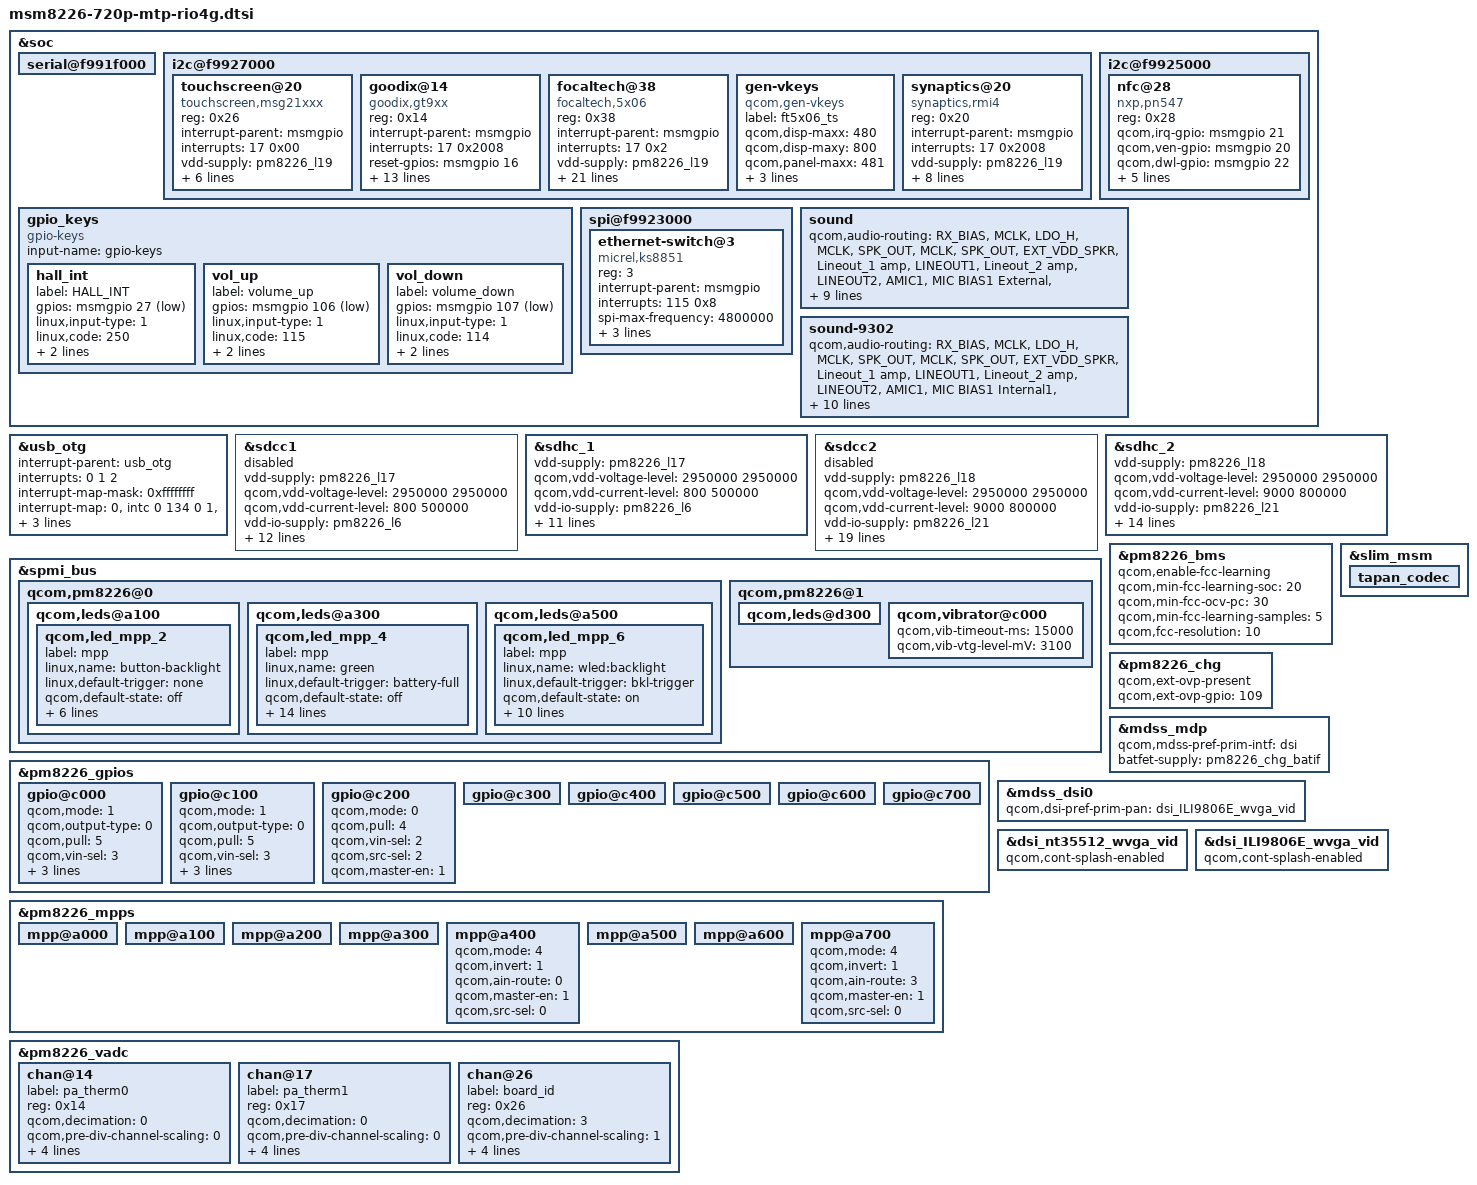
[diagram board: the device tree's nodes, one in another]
/* Copyright (c) 2013, The Linux Foundation. All rights reserved.
 *
 * This program is free software; you can redistribute it and/or modify
 * it under the terms of the GNU General Public License version 2 and
 * only version 2 as published by the Free Software Foundation.
 *
 * This program is distributed in the hope that it will be useful,
 * but WITHOUT ANY WARRANTY; without even the implied warranty of
 * MERCHANTABILITY or FITNESS FOR A PARTICULAR PURPOSE.  See the
 * GNU General Public License for more details.
 */

/* [PLATFORM]-Mod-BEGIN by TCTNB.WQF, 2013/08/15, rename the camera dtsi for rio4g */
/include/ "msm8226-camera-sensor-mtp-rio4g.dtsi"
/* [PLATFORM]-Mod-END by TCTNB.WQF */

&soc {
	serial@f991f000 {
		status = "ok";
	};

	i2c@f9927000 { /* BLSP1 QUP5 */
/*[PLATFORM]-ADD BGEIN by TCTNB.XQJ,07/31/2013,FR-487707,msg21 tp development,i2c address to 0x26.*/
                touchscreen@20 {
			compatible = "touchscreen,msg21xxx";
			reg = <0x26>;
			interrupt-parent = <&msmgpio>;
			interrupts = <17 0x00>;
			vdd-supply = <&pm8226_l19>;
			vcc_i2c-supply = <&pm8226_lvs1>;
			touchscreen,reset-gpio = <&msmgpio 16 0x00>;
			touchscreen,irq-gpio = <&msmgpio 17 0x00>;
			touchscreen,i2c-pull-up;
                        touchscreen,x_max=<480>;
                        touchscreen,y_max=<854>;
		};
/*[PLATFORM]-END by TCTNB.XQJ*/

/*[PLATFORM]-ADD BGEIN by TCTNB.XQJ,10/13/2013,FR-514195,GT915 tp MIATA development,i2c address to 0x14.,new cfg*/
	goodix@14 {
			compatible = "goodix,gt9xx";
			reg = <0x14>;
			interrupt-parent = <&msmgpio>;
			interrupts = <17 0x2008>;
			reset-gpios = <&msmgpio 16 0x00>;
			interrupt-gpios = <&msmgpio 17 0x00>;
                        vcc_i2c-supply = <&pm8226_lvs1>;
			avdd-supply =<&pm8226_l19>;/* <&tp_power>;*/
                        vdd-supply = <&pm8226_l19>;
			goodix,panel-coords =<0 0 540 1080>;
			goodix,display-coords = <0 0 540 960>;
			goodix,button-map= <158 102 139>;
                        regulator-min-microvolt = <2800000>;
                        regulator-max-microvolt = <2800000>;
			goodix,family-id = <0x0>;
                        goodix,i2c-pull-up;
			goodix,cfg-data = [ /*[BUGFIX]-MOD by TCTNB.XQJ,10/28/2013,FR-545213,double click wake,new cfg*/
                       45 1C 02 C0 03 05 34 01 01 0F 14 5F 3C 2D 03 05 00 00 00 00 88 
                       00 00 15 18 1D 14 8A 0A 0A 34 32 D3 07 00 00 00 83 02 1D 3C 01
                       00 00 00 00 00 00 00 00 00 28 64 94 C5 02 02 08 00 04 94 2C 00 
                       80 34 00 6C 3F 00 5D 4C 00 51 5B 00 51 10 30 48 00 F0 40 30 AA 
                       AA 27 00 00 00 00 00 00 00 00 00 00 00 00 00 00 00 00 00 00 00
                       00 00 00 00 00 00 00 02 04 06 08 0A 0C 0E 14 12 10 FF FF FF FF 
                       00 00 00 00 00 00 00 00 00 00 00 00 00 00 00 00 24 18 22 1C 21 
                       1D 20 1E 1F 16 02 0F 04 10 06 12 08 13 0A 00 FF FF FF FF FF FF
                       00 00 00 F5 FF FF FF FF FF FF FF FF 95 FF FF FF 7E 01
	         	];
		};
/*[PLATFORM]-END by TCTNB.XQJ*/
/*[PLATFORM]-MOD BGEIN by TCTNB.XQJ,12/06/2013,FR-553303,Add driver ft5x06.*/
       focaltech@38 {
			compatible ="focaltech,5x06";
			reg = <0x38>;
			interrupt-parent = <&msmgpio>;
			interrupts = <17 0x2>;
			vdd-supply = <&pm8226_l19>;
			vcc_i2c-supply = <&pm8226_lvs1>;
                        focaltech,name = "ft5x06";
			focaltech,family-id = <0x06>;
			focaltech,reset-gpio = <&msmgpio 16 0x00>;
                        focaltech,wake-gpio = <&msmgpio 5 0x00>;/*[BUGFIX]-ADD by TCTNB.XQJ,11/07/2013,FR-529341,for wakeup pin gpio problem ,note temprory.*/
			focaltech,irq-gpio = <&msmgpio 17 0x00>;
			focaltech,display-coords = <0 0 480 800>;
			focaltech,panel-coords = <0 0 480 920>;
			focaltech,button-map= <139 102 158>;
			focaltech,no-force-update;
			focaltech,i2c-pull-up;
                        focaltech,group-id = <1>;
			focaltech,hard-reset-delay-ms = <20>;
			focaltech,soft-reset-delay-ms = <150>;
			focaltech,num-max-touches = <2>;
			/*focaltech,fw-name = "";*/
			focaltech,fw-delay-aa-ms = <100>;
			focaltech,fw-delay-55-ms = <30>;
			focaltech,fw-upgrade-id1 = <0x79>;
			focaltech,fw-upgrade-id2 = <0x08>;
			focaltech,fw-delay-readid-ms = <10>;
			focaltech,fw-delay-era-flsh-ms = <2000>;
		};


	gen-vkeys {
		compatible = "qcom,gen-vkeys";
		label = "ft5x06_ts";
		qcom,disp-maxx = <480>;
		qcom,disp-maxy = <800>;
		qcom,panel-maxx = <481>;
		qcom,panel-maxy = <920>;
		qcom,key-codes = <139 102 158>;
		qcom,y-offset = <0>;
	};
/*[PLATFORM]-END by TCTNB.XQJ*/
		synaptics@20 {
			compatible = "synaptics,rmi4";
			reg = <0x20>;
			interrupt-parent = <&msmgpio>;
			interrupts = <17 0x2008>;
			vdd-supply = <&pm8226_l19>;
			vcc_i2c-supply = <&pm8226_lvs1>;
			synaptics,reset-gpio = <&msmgpio 16 0x00>;
			synaptics,irq-gpio = <&msmgpio 17 0x2008>;
			synaptics,button-map = <139 102 158>;
			synaptics,fw-image-name = "PR1468813.img";
			synaptics,i2c-pull-up;
			synaptics,power-down;
			synaptics,disable-gpios;
		};
	};
/*[FEATURE]-Add-BEGIN by TCTNB.YuBin, 2013/10/18, FR515461, Add NFC function.*/
	i2c@f9925000 { /* BLSP1 QUP3 */
		nfc@28 {
			compatible = "nxp,pn547";
			reg = <0x28>;
			qcom,irq-gpio = <&msmgpio 21 0x00>;
			qcom,ven-gpio = <&msmgpio 20 0x00>;
			qcom,dwl-gpio = <&msmgpio 22 0x00>;
			qcom,clk-src = "BBCLK2";
			qcom,clk-en-gpio = <&msmgpio 0 0x00>;
			interrupt-parent = <&msmgpio>;
			interrupts = <21 0>;
			qcom,clk-gpio = <&pm8226_gpios 3 0>;
		};
	};
/*[FEATURE]-Add-END by TCTNB.YuBin*/
	gpio_keys {
		compatible = "gpio-keys";
		input-name = "gpio-keys";

/* [PLATFORM]-ADD-BEGIN by TCTNB.WJ, 2014/1/21, CR-591965, dev for Hall */
		hall_int {
			label = "HALL_INT";
			gpios = <&msmgpio 27 0x1>;
			linux,input-type = <1>;
			linux,code = <250>;
			gpio-key,wakeup;
			debounce-interval = <15>;
		};
/* [PLATFORM]-ADD-END by TCTNB.WJ */

/* [PLATFORM]-Del-BEGIN by TCTNB.WPL, 2013/08/20, refer to bug505571 */
/*
		camera_focus {
			label = "camera_focus";
			gpios = <&msmgpio 108 0x1>;
			linux,input-type = <1>;
			linux,code = <0x210>;
			gpio-key,wakeup;
			debounce-interval = <15>;
		};

		camera_snapshot {
			label = "camera_snapshot";
			gpios = <&msmgpio 107 0x1>;
			linux,input-type = <1>;
			linux,code = <0x2fe>;
			gpio-key,wakeup;
			debounce-interval = <15>;
		};
*/
/* [PLATFORM]-Del-END by TCTNB.WPL */

		vol_up {
			label = "volume_up";
			gpios = <&msmgpio 106 0x1>;
			linux,input-type = <1>;
			linux,code = <115>;
			gpio-key,wakeup;
			debounce-interval = <15>;
		};

/* [PLATFORM]-Add-BEGIN by TCTNB.WPL, 2013/08/20, refer to bug505571 */
		vol_down {
			label = "volume_down";
			gpios = <&msmgpio 107 0x1>;
			linux,input-type = <1>;
			linux,code = <114>;
			gpio-key,wakeup;
			debounce-interval = <15>;
		};
/* [PLATFORM]-Add-END by TCTNB.WPL */
	};

	spi@f9923000 {
		ethernet-switch@3 {
			compatible = "micrel,ks8851";
			reg = <3>;
			interrupt-parent = <&msmgpio>;
			interrupts = <115 0x8>;
			spi-max-frequency = <4800000>;
			rst-gpio = <&msmgpio 114 0>;
			vdd-io-supply = <&pm8226_lvs1>;
			vdd-phy-supply = <&pm8226_lvs1>;
		};
	};

	sound {
		qcom,audio-routing =
			"RX_BIAS", "MCLK",
			"LDO_H", "MCLK",
			"SPK_OUT", "MCLK",
			"SPK_OUT", "EXT_VDD_SPKR",
/* [PLATFORM]-Mod-BEGIN by TCTNB.WQF, 2013/08/15, Add lineout speaker control */
			"Lineout_1 amp", "LINEOUT1",
			"Lineout_2 amp", "LINEOUT2",
/* [PLATFORM]-Mod-END by TCTNB.WQF */
			"AMIC1", "MIC BIAS1 External",
			"MIC BIAS1 External", "Handset Mic",
			"AMIC2", "MIC BIAS2 External",
			"MIC BIAS2 External", "Headset Mic",
			"AMIC4", "MIC BIAS2 External",
			"MIC BIAS2 External", "ANCRight Headset Mic",
			"AMIC5", "MIC BIAS2 External",
			"MIC BIAS2 External", "ANCLeft Headset Mic";

		qcom,cdc-mclk-gpios = <&pm8226_gpios 1 0>;
/* [PLATFORM]-Mod-BEGIN by TCTNB.WQF, 2013/08/15, Add lineout speaker control */
/*		qcom,cdc-vdd-spkr-gpios = <&pm8226_gpios 2 0>;*/
		qcom,cdc-lineout-spkr-gpios = <&pm8226_gpios 2 0>; /* modify by changshun.zhou for open speaker amp 20140114 */
/* [PLATFORM]-Mod-END by TCTNB.WQF */
/* [PLATFORM]-Mod-BEGIN by TCTNB.WQF, 2013/08/21, Add hac control */
		qcom,cdc-hac-gpios = <&msmgpio 69 0>;
/* [PLATFORM]-Mod-END by TCTNB.WQF */
	};

	sound-9302 {
		qcom,audio-routing =
			"RX_BIAS", "MCLK",
			"LDO_H", "MCLK",
			"SPK_OUT", "MCLK",
			"SPK_OUT", "EXT_VDD_SPKR",
/* [PLATFORM]-Mod-BEGIN by TCTNB.WQF, 2013/08/15, Add lineout speaker control */
			"Lineout_1 amp", "LINEOUT1",
			"Lineout_2 amp", "LINEOUT2",
/* [PLATFORM]-Mod-END by TCTNB.WQF */
			"AMIC1", "MIC BIAS1 Internal1",
			"MIC BIAS1 Internal1", "Handset Mic",
			"AMIC2", "MIC BIAS2 External",
			"MIC BIAS2 External", "Headset Mic",
			"AMIC3", "MIC BIAS1 External",
			"MIC BIAS1 External", "Handset Mic",
/* [PLATFORM]-Mod-BEGIN by TCTNB.WQF, 2013/10/15, Add dmic control */
			"DMIC1", "MIC BIAS1 External",
			"MIC BIAS1 External", "Digital Mic1",
			"DMIC2", "MIC BIAS1 External",
			"MIC BIAS1 External", "Digital Mic2";
/* [PLATFORM]-Mod-END by TCTNB.WQF */

		qcom,cdc-mclk-gpios = <&pm8226_gpios 1 0>;
/* [PLATFORM]-Mod-BEGIN by TCTNB.WQF, 2013/08/15, Add lineout speaker control */
/*		qcom,cdc-vdd-spkr-gpios = <&pm8226_gpios 2 0>;*/
		qcom,cdc-lineout-spkr-gpios = <&pm8226_gpios 2 0>; /* modify by changshun.zhou for open speaker amp 20140114 */
/* [PLATFORM]-Mod-END by TCTNB.WQF */
/* [PLATFORM]-Mod-BEGIN by TCTNB.WQF, 2013/08/21, Add hac control */
		qcom,cdc-hac-gpios = <&msmgpio 69 0>;
/* [PLATFORM]-Mod-END by TCTNB.WQF */
	};
};

&usb_otg {
	#address-cells = <0>;
	interrupt-parent = <&usb_otg>;
	interrupts = <0 1 2>;
	#interrupt-cells = <1>;
	interrupt-map-mask = <0xffffffff>;
	interrupt-map = <0 &intc 0 134 0
			1 &intc 0 140 0
			2 &spmi_bus 0x0 0x0 0x9 0x0>;
	interrupt-names = "core_irq", "async_irq", "pmic_id_irq";

	qcom,hsusb-otg-mode = <3>;
	vbus_otg-supply = <&pm8226_chg_otg>;
};

&sdcc1 {
	vdd-supply = <&pm8226_l17>;
	qcom,vdd-voltage-level = <2950000 2950000>;
	qcom,vdd-current-level = <800 500000>;

	vdd-io-supply = <&pm8226_l6>;
	qcom,vdd-io-always-on;
	qcom,vdd-io-voltage-level = <1800000 1800000>;
	qcom,vdd-io-current-level = <250 154000>;

	qcom,pad-pull-on = <0x0 0x3 0x3>; /* no-pull, pull-up, pull-up */
	qcom,pad-pull-off = <0x0 0x3 0x3>; /* no-pull, pull-up, pull-up */
	qcom,pad-drv-on = <0x4 0x4 0x4>; /* 10mA, 10mA, 10mA */
	qcom,pad-drv-off = <0x0 0x0 0x0>; /* 2mA, 2mA, 2mA */

	qcom,clk-rates = <400000 25000000 50000000 100000000 200000000>;
	qcom,sup-voltages = <2950 2950>;

	qcom,bus-speed-mode = "HS200_1p8v", "DDR_1p8v";
	qcom,nonremovable;

	status = "disabled";
};

&sdhc_1 {
	vdd-supply = <&pm8226_l17>;
	qcom,vdd-voltage-level = <2950000 2950000>;
	qcom,vdd-current-level = <800 500000>;

	vdd-io-supply = <&pm8226_l6>;
	qcom,vdd-io-always-on;
	qcom,vdd-io-voltage-level = <1800000 1800000>;
	qcom,vdd-io-current-level = <250 154000>;

	qcom,pad-pull-on = <0x0 0x3 0x3>; /* no-pull, pull-up, pull-up */
	qcom,pad-pull-off = <0x0 0x3 0x3>; /* no-pull, pull-up, pull-up */
	qcom,pad-drv-on = <0x4 0x4 0x4>; /* 10mA, 10mA, 10mA */
	qcom,pad-drv-off = <0x0 0x0 0x0>; /* 2mA, 2mA, 2mA */

	qcom,clk-rates = <400000 25000000 50000000 100000000 200000000>;
	qcom,bus-speed-mode = "HS200_1p8v", "DDR_1p8v";
	qcom,nonremovable;

	status = "ok";
};

&sdcc2 {
	vdd-supply = <&pm8226_l18>;
	qcom,vdd-voltage-level = <2950000 2950000>;
	qcom,vdd-current-level = <9000 800000>;

	vdd-io-supply = <&pm8226_l21>;
	qcom,vdd-io-voltage-level = <1800000 2950000>;
	qcom,vdd-io-current-level = <6 22000>;

	qcom,pad-pull-on = <0x0 0x3 0x3>; /* no-pull, pull-up, pull-up */
	qcom,pad-pull-off = <0x0 0x3 0x3>; /* no-pull, pull-up, pull-up */
	qcom,pad-drv-on = <0x4 0x4 0x4>; /* 10mA, 10mA, 10mA */
	qcom,pad-drv-off = <0x0 0x0 0x0>; /* 2mA, 2mA, 2mA */

	qcom,clk-rates = <400000 25000000 50000000 100000000 200000000>;
	qcom,sup-voltages = <2950 2950>;

	qcom,xpc;
	qcom,bus-speed-mode = "SDR12", "SDR25", "SDR50", "DDR50", "SDR104";
	qcom,current-limit = <600>; #address-cells = <0>; interrupt-parent = <&sdcc2>;
	interrupts = <0 1 2>;
	#interrupt-cells = <1>;
	interrupt-map-mask = <0xffffffff>;
	interrupt-map = <0 &intc 0 125 0
			1 &intc 0 220 0
			2 &msmgpio 38 0x3>;
	interrupt-names = "core_irq", "bam_irq", "status_irq";
	cd-gpios = <&msmgpio 38 0x1>;

	status = "disabled";
};

&sdhc_2 {
	vdd-supply = <&pm8226_l18>;
	qcom,vdd-voltage-level = <2950000 2950000>;
	qcom,vdd-current-level = <9000 800000>;

	vdd-io-supply = <&pm8226_l21>;
	qcom,vdd-io-voltage-level = <1800000 2950000>;
	qcom,vdd-io-current-level = <6 22000>;

	qcom,pad-pull-on = <0x0 0x3 0x3>; /* no-pull, pull-up, pull-up */
	qcom,pad-pull-off = <0x0 0x3 0x3>; /* no-pull, pull-up, pull-up */
	qcom,pad-drv-on = <0x4 0x4 0x4>; /* 10mA, 10mA, 10mA */
	qcom,pad-drv-off = <0x0 0x0 0x0>; /* 2mA, 2mA, 2mA */

	qcom,clk-rates = <400000 25000000 50000000 100000000 200000000>;

	#address-cells = <0>;
	interrupt-parent = <&sdhc_2>;
	interrupts = <0 1 2>;
	#interrupt-cells = <1>;
	interrupt-map-mask = <0xffffffff>;
	interrupt-map = <0 &intc 0 125 0
			1 &intc 0 221 0
			2 &msmgpio 38 0x3>;
	interrupt-names = "hc_irq", "pwr_irq", "status_irq";
	cd-gpios = <&msmgpio 38 0x1>;

	status = "ok";
};

&spmi_bus {
	qcom,pm8226@0 {
		qcom,leds@a100 {
			status = "okay";
			qcom,led_mpp_2 {
				label = "mpp";
				linux,name = "button-backlight";
				linux,default-trigger = "none";
				qcom,default-state = "off";
				qcom,max-current = <40>;
				qcom,current-setting = <5>;
				qcom,id = <6>;
				qcom,mode = "manual";
				qcom,source-sel = <1>;
				qcom,mode-ctrl = <0x60>;
			};
		};

		qcom,leds@a300 {
			status = "okay";
			qcom,led_mpp_4 {
				label = "mpp";
				linux,name = "green";
				linux,default-trigger = "battery-full";
				qcom,default-state = "off";
				qcom,max-current = <40>;
				qcom,current-setting = <5>;
				qcom,id = <6>;
/*[BUGFIX]-MOD-BEGIN by TCTNB.XQJ,FR-510131 2013/9/12, modify attribute interface with  charge LED and incident LED*/
                                qcom,mode = "lpg";
                                qcom,pwm-us = <1000>;
                                qcom,source-sel = <8>;
                                qcom,mode-ctrl = <0x60>;
                                qcom,pwm-channel = <0>;
                                qcom,start-idx = <1>;
                                qcom,ramp-step-ms = <499>;
                                qcom,idx-len = <16>;
                                qcom,duty-pcts = [00 00 10 20 40 64 64 40 20 10 00 00];
/*[BUGFIX]-Mod-END by TCTNB.XQJ*/
				qcom,use-blink;
			};
		};

		qcom,leds@a500 {
			status = "okay";
			qcom,led_mpp_6 {
				label = "mpp";
/* [PLATFORM]-Mod-BEGIN by TCTNB.WQF, 2013/8/8, Modify backlight control */
				linux,name = "wled:backlight";
				linux,default-trigger = "bkl-trigger";
				qcom,default-state = "on";
				qcom,max-current = <40>;
				qcom,current-setting = <5>;
				qcom,id = <6>;
				qcom,source-sel = <10>;
				qcom,mode-ctrl = <0x10>;
				qcom,pwm-channel = <5>;
				qcom,pwm-us = <511>;
				qcom,vin-ctrl = <0x03>;
				qcom,mode = "pwm";
				qcom,min-brightness = <19>;
/*
				linux,name = "red";
				linux,default-trigger = "battery-charging";
				qcom,default-state = "off";
				qcom,max-current = <40>;
				qcom,current-setting = <5>;
				qcom,id = <6>;
				qcom,mode = "pwm";
				qcom,pwm-us = <1000>;
				qcom,mode-ctrl = <0x60>;
				qcom,source-sel = <10>;
				qcom,pwm-channel = <5>;
				qcom,start-idx = <1>;
				qcom,ramp-step-ms = <120>;
				qcom,duty-pcts = [00 00 00 00 00
						  00 00 00 00 00
						  50 00 00 00 00
						  00 00 00 00 00
						  00];
				qcom,use-blink;
*/
/* [PLATFORM]-Mod-END by TCTNB.WQF */
			};
		};
	};

	qcom,pm8226@1 {
                qcom,leds@d300 {
                        status = "okay";
                };

/* [PLATFORM]-Del-BEGIN by TCTNB.WQF, 2013/8/8, Modify backlight control */
/*
		qcom,leds@d800 {
			status = "okay";
			qcom,wled_0 {
				label = "wled";
				linux,name = "wled:backlight";
				linux,default-trigger = "bkl-trigger";
				qcom,cs-out-en;
				qcom,op-fdbck = <1>;
				qcom,default-state = "on";
				qcom,max-current = <20>;
				qcom,ctrl-delay-us = <0>;
				qcom,boost-curr-lim = <3>;
				qcom,cp-sel = <0>;
				qcom,switch-freq = <11>;
				qcom,ovp-val = <0>;
				qcom,num-strings = <1>;
				qcom,id = <0>;
			};
		};
*/
/* [PLATFORM]-Del-END by TCTNB.WQF */

/* [PLATFORM]-Add-BEGIN by TCTNB.WQF, 2013/08/23, Add vibrator device */
		qcom,vibrator@c000 {
			status = "okay";
			qcom,vib-timeout-ms = <15000>;
			qcom,vib-vtg-level-mV = <3100>;
		};
/* [PLATFORM]-Add-END by TCTNB.WQF */
	};
};

&pm8226_gpios {
	gpio@c000 { /* GPIO 1 */
		/* XO_PMIC_CDC_MCLK enable for tapan codec */
		qcom,mode = <1>;		/* Digital output */
		qcom,output-type = <0>;	/* CMOS logic */
		qcom,pull = <5>;		/* QPNP_PIN_PULL_NO*/
		qcom,vin-sel = <3>;		/* QPNP_PIN_VIN3 */
		qcom,out-strength = <3>;/* QPNP_PIN_OUT_STRENGTH_HIGH */
		qcom,src-sel = <2>;		/* QPNP_PIN_SEL_FUNC_1 */
		qcom,master-en = <1>;	/* Enable GPIO */
	};

	gpio@c100 { /* GPIO 2 */
		qcom,mode = <1>;
		qcom,output-type = <0>;
		qcom,pull = <5>;
		qcom,vin-sel = <3>;
		qcom,out-strength = <3>;
		qcom,src-sel = <2>;
		qcom,master-en = <1>;
	};

	gpio@c200 { /* GPIO 3 */
		qcom,mode = <0>;		/* QPNP_PIN_MODE_DIG_IN */
		qcom,pull = <4>;		/* QPNP_PIN_PULL_DOWN *//* [PLATFORM]-Add-BEGIN by TCTNB.YuBin, 2013/11/27, ref bug561481 */
		qcom,vin-sel = <2>;		/* QPNP_PIN_VIN2 */
		qcom,src-sel = <2>;		/* QPNP_PIN_SEL_FUNC_1 */
		qcom,master-en = <1>;
	};

	gpio@c300 { /* GPIO 4 */
	};

	gpio@c400 { /* GPIO 5 */
	};

	gpio@c500 { /* GPIO 6 */
	};

	gpio@c600 { /* GPIO 7 */
	};

	gpio@c700 { /* GPIO 8 */
	};
};

&pm8226_mpps {
	mpp@a000 { /* MPP 1 */
	};

	mpp@a100 { /* MPP 2 */
	};

	mpp@a200 { /* MPP 3 */
	};

	mpp@a300 { /* MPP 4 */
	};

	mpp@a400 { /* MPP 5 */
		/* PA_THERM0 config */
		qcom,mode = <4>; /* AIN input */
		qcom,invert = <1>; /* Enable MPP */
		qcom,ain-route = <0>; /* AMUX 5 */
		qcom,master-en = <1>;
		qcom,src-sel = <0>; /* Function constant */
	};

	mpp@a500 { /* MPP 6 */
	};

	mpp@a600 { /* MPP 7 */
	};

	mpp@a700 { /* MPP 8 */
		/* PA_THERM1 config */
		qcom,mode = <4>; /* AIN input */
		qcom,invert = <1>; /* Enable MPP */
		qcom,ain-route = <3>; /* AMUX 8 */
		qcom,master-en = <1>;
		qcom,src-sel = <0>; /* Function constant */
	};
};

&pm8226_vadc {
	chan@14 {
		label = "pa_therm0";
		reg = <0x14>;
		qcom,decimation = <0>;
		qcom,pre-div-channel-scaling = <0>;
		qcom,calibration-type = "ratiometric";
		qcom,scale-function = <2>;
		qcom,hw-settle-time = <2>;
		qcom,fast-avg-setup = <0>;
	};

	chan@17 {
		label = "pa_therm1";
		reg = <0x17>;
		qcom,decimation = <0>;
		qcom,pre-div-channel-scaling = <0>;
		qcom,calibration-type = "ratiometric";
		qcom,scale-function = <2>;
		qcom,hw-settle-time = <2>;
		qcom,fast-avg-setup = <0>;
	};

/* [PLATFORM]-Add-BEGIN by TCTNB.WQF, 2013/8/8, Add board id detection */
	chan@26 {
		label = "board_id";
		reg = <0x26>;
		qcom,decimation = <3>;
		qcom,pre-div-channel-scaling = <1>;
		qcom,calibration-type = "absolute";
		qcom,scale-function = <0>;
		qcom,hw-settle-time = <0>;
		qcom,fast-avg-setup = <0>;
	};
/* [PLATFORM]-Add-END by TCTNB.WQF */
};

/* [PLATFORM]-Mod-BEGIN by TCTNB.YuBin, 2013/12/19, using battery data in c file */
/*/ {*/
/*	mtp_batterydata: qcom,battery-data {*/
/*		qcom,rpull-up-kohm = <100>;*/
/*		qcom,vref-batt-therm = <1800000>;*/

/*		/include/ "batterydata-palladium.dtsi"*/
/*		/include/ "batterydata-mtp-3000mah.dtsi"*/
/* [PLATFORM]-Add-BEGIN by TCTNB.YuBin, 2013/12/05, temp using , when HW provide battery data , need to remove it  */
/*		/include/ "batterydata-miata-temporary-byd.dtsi"*/
/*		/include/ "batterydata-miata-temporary-scud.dtsi"*/
/* [PLATFORM]-Add-END by TCTNB.YuBin */
/*	};*/
/*};*/
/* [PLATFORM]-Add-END by TCTNB.YuBin */

&pm8226_bms {
	status = "ok";
	qcom,enable-fcc-learning;
	qcom,min-fcc-learning-soc = <20>;
	qcom,min-fcc-ocv-pc = <30>;
	qcom,min-fcc-learning-samples = <5>;
	qcom,fcc-resolution = <10>;
/* [PLATFORM]-Mod-BEGIN by TCTNB.YuBin, 2013/12/19, using battery data in c file */
	//qcom,battery-data = <&mtp_batterydata>;
/* [PLATFORM]-Mod-END by TCTNB.YuBin */
};

&pm8226_chg {
/* [PLATFORM]-Mod-BEGIN by TCTNB.YuBin, 2013/08/20, refer to bug509980, Enable charging */
/*	qcom,charging-disabled;	*/
/* [PLATFORM]-Mod-END by TCTNB.YuBin */
/* [PLATFORM]-Mod-BEGIN by TCTNB.YuBin, 2013/12/05, merge from miata */
	qcom,ext-ovp-present;
	qcom,ext-ovp-gpio = <109>;
/* [PLATFORM]-Mod-END by TCTNB.YuBin */
/* [PLATFORM]-Mod-BEGIN by TCTNB.YuBin, 2013/12/19, using battery data in c file */
	//qcom,battery-data = <&mtp_batterydata>;
/* [PLATFORM]-Mod-END by TCTNB.YuBin */
};

&slim_msm {
	tapan_codec {
/* [PLATFORM]-Mod-BEGIN by TCTNB.WQF, 2013/08/21, Modify the bias1_cap_mode */
/*		qcom,cdc-micbias1-ext-cap;*/
/* [PLATFORM]-Mod-END by TCTNB.WQF */
	};
};

&mdss_mdp {
	qcom,mdss-pref-prim-intf = "dsi";
	batfet-supply = <&pm8226_chg_batif>;
};

&mdss_dsi0 {
	qcom,dsi-pref-prim-pan = <&dsi_ILI9806E_wvga_vid>;
};

/*
&mdss_dsi0 {
	qcom,dsi-pref-prim-pan = <&dsi_ILI9806E_wvga_vid>;
};
*/

&dsi_nt35512_wvga_vid {
/* [PLATFORM]-Add-BEGIN by TCTNB.FLF, PR-548695, 2013/12/05, add lcd nt35512 for rio4g */
	qcom,cont-splash-enabled;
/* [PLATFORM]-Del-END by TCTNB.WPL */
};

&dsi_ILI9806E_wvga_vid {
/* [PLATFORM]-Add-BEGIN by jie.wang, 2014/02/17, add lcd ILI9806E for rio4g */
	qcom,cont-splash-enabled;
/* [PLATFORM]-Del-END by jie.wang */
};
